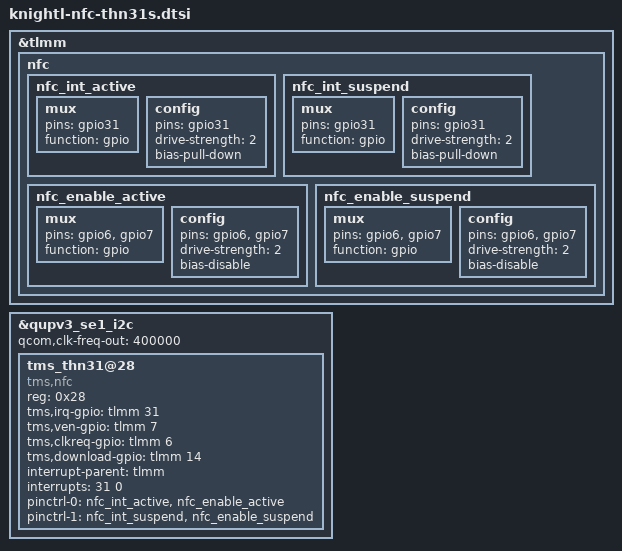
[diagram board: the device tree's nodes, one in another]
/**********************************************************************************
* Copyright (c)  2008-2020  Guangdong oplus Mobile Comm Corp., Ltd
* Description: oplus sn220e nfc dtsi
*
***********************************************************************************/
&tlmm {
  nfc {
         nfc_int_active: nfc_int_active {
                 /* active state */
                 mux {
                         /* GPIO 31: NFC Read Interrupt */
                         pins = "gpio31";
                         function = "gpio";
                     };

                 config {
                         pins = "gpio31";
                         drive-strength = <2>; /* 2 MA */
                         bias-pull-down;
                        };
         };

         nfc_int_suspend: nfc_int_suspend {
                 /* sleep state */
                 mux {
                         /* GPIO 31: NFC Read Interrupt */
                         pins = "gpio31";
                         function = "gpio";
                     };

                 config {
                         pins = "gpio31";
                         drive-strength = <2>; /* 2 MA */
                         bias-pull-down;
                        };
         };

         nfc_enable_active: nfc_enable_active {
                 mux {
                         /* 6: Enable,  7: CLOCK */
                         pins = "gpio6", "gpio7";
                         function = "gpio";
                     };

                 config {
                         pins = "gpio6", "gpio7";
                         drive-strength = <2>; /* 2 MA */
                         bias-disable;
                        };
         };

         nfc_enable_suspend: nfc_enable_suspend {
                 mux {
                         /* 6: Enable, 7: CLOCK */
                         pins = "gpio6", "gpio7";
                         function = "gpio";
                     };

                 config {
                         pins = "gpio6", "gpio7";
                         drive-strength = <2>; /* 2 MA */
                         bias-disable;
                        };
         };
    };
};


&qupv3_se1_i2c {
	status = "ok";
	qcom,clk-freq-out = <400000>;
	#address-cells = <1>;
	#size-cells = <0>;
	tms_thn31@28 {
		compatible = "tms,nfc";
		reg = <0x28>;
		tms,irq-gpio = <&tlmm 31 0x00>;
		tms,ven-gpio = <&tlmm 7 0x00>;
		tms,clkreq-gpio = <&tlmm 6 0x00>;
		tms,download-gpio = <&tlmm 14 0x00>;
		interrupt-parent = <&tlmm>;
		interrupts = <31 0>;
		interrupt-names = "nfc_irq";
		pinctrl-names = "nfc_active", "nfc_suspend";
		pinctrl-0 = <&nfc_int_active &nfc_enable_active>;
		pinctrl-1 = <&nfc_int_suspend &nfc_enable_suspend>;
	};
};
